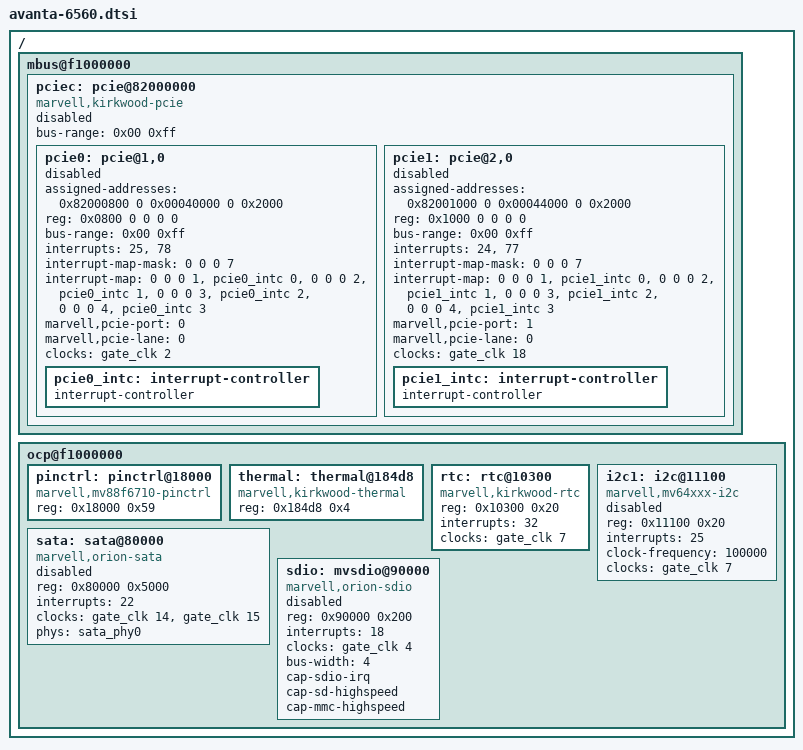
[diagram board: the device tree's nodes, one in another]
// SPDX-License-Identifier: GPL-2.0
/*
 *   (c) 2022 winnt5 <jiconglu58@gmail.com>
 *
 * Based on
 *
 * Copyright (c) 2021, bodhi <mibodhi@gmail.com>
 *
 * Based on    
 *   (c) 2015 Claudio Leite <leitec@staticky.com>
 *
 * Values derived from Marvell GPL source release, from Actiontec MI-424WR
 * source code,
 *
 *   Copyright (C) Marvell International Ltd. and its affiliates
 *
 * This file is licensed under the terms of the GNU General Public
 * License version 2.  This program is licensed "as is" without any
 * warranty of any kind, whether express or implied.
 */

/ {
	mbus@f1000000 {
		pciec: pcie@82000000 {
			compatible = "marvell,kirkwood-pcie";
			status = "disabled";
			device_type = "pci";

			#address-cells = <3>;
			#size-cells = <2>;

			bus-range = <0x00 0xff>;

			ranges =
			       <0x82000000 0 0x40000 MBUS_ID(0xf0, 0x01) 0x40000 0 0x00002000
			        0x82000000 0 0x44000 MBUS_ID(0xf0, 0x01) 0x44000 0 0x00002000
				0x82000000 0 0x80000 MBUS_ID(0xf0, 0x01) 0x80000 0 0x00002000
				0x82000000 0x1 0     MBUS_ID(0x04, 0xe8) 0       1 0 /* Port 0.0 MEM */
				0x81000000 0x1 0     MBUS_ID(0x04, 0xe0) 0       1 0 /* Port 0.0 IO  */
				0x82000000 0x2 0     MBUS_ID(0x04, 0xd8) 0       1 0 /* Port 1.0 MEM */
				0x81000000 0x2 0     MBUS_ID(0x04, 0xd0) 0       1 0 /* Port 1.0 IO  */>;

			pcie0: pcie@1,0 {
				device_type = "pci";
				assigned-addresses = <0x82000800 0 0x00040000 0 0x2000>;
				reg = <0x0800 0 0 0 0>;
				#address-cells = <3>;
				#size-cells = <2>;
				#interrupt-cells = <1>;
				ranges = <0x82000000 0 0 0x82000000 0x1 0 1 0
					  0x81000000 0 0 0x81000000 0x1 0 1 0>;
				bus-range = <0x00 0xff>;
				interrupt-names = "intx", "error";
				interrupts = <25>, <78>;
				interrupt-map-mask = <0 0 0 7>;
				interrupt-map = <0 0 0 1 &pcie0_intc 0>,
						<0 0 0 2 &pcie0_intc 1>,
						<0 0 0 3 &pcie0_intc 2>,
						<0 0 0 4 &pcie0_intc 3>;
				marvell,pcie-port = <0>;
				marvell,pcie-lane = <0>;
				clocks = <&gate_clk 2>;
				status = "disabled";

				pcie0_intc: interrupt-controller {
					interrupt-controller;
					#interrupt-cells = <1>;
				};
			};

			pcie1: pcie@2,0 {
				device_type = "pci";
				assigned-addresses = <0x82001000 0 0x00044000 0 0x2000>;
				reg = <0x1000 0 0 0 0>;
				#address-cells = <3>;
				#size-cells = <2>;
				#interrupt-cells = <1>;
				ranges = <0x82000000 0 0 0x82000000 0x2 0 1 0
					  0x81000000 0 0 0x81000000 0x2 0 1 0>;
				bus-range = <0x00 0xff>;
				interrupt-names = "intx", "error";
				interrupts = <24>, <77>;
				interrupt-map-mask = <0 0 0 7>;
				interrupt-map = <0 0 0 1 &pcie1_intc 0>,
						<0 0 0 2 &pcie1_intc 1>,
						<0 0 0 3 &pcie1_intc 2>,
						<0 0 0 4 &pcie1_intc 3>;
				marvell,pcie-port = <1>;
				marvell,pcie-lane = <0>;
				clocks = <&gate_clk 18>;
				status = "disabled";

				pcie1_intc: interrupt-controller {
					interrupt-controller;
					#interrupt-cells = <1>;
				};
			};
		};
	};
	ocp@f1000000 {
		pinctrl: pinctrl@18000 {
			compatible = "marvell,mv88f6710-pinctrl";
			reg = <0x18000 0x59>;
		};

		thermal: thermal@184d8 {
			compatible = "marvell,kirkwood-thermal";
			reg = <0x184d8 0x4>;
			status = "okay";
		};

		rtc: rtc@10300 {
			compatible = "marvell,kirkwood-rtc", "marvell,orion-rtc";
			reg = <0x10300 0x20>;
			interrupts = <32>;
			clocks = <&gate_clk 7>;
		};

		i2c1: i2c@11100 {
			compatible = "marvell,mv64xxx-i2c";
			reg = <0x11100 0x20>;
			#address-cells = <1>;
			#size-cells = <0>;
			interrupts = <25>;
			clock-frequency = <100000>;
			clocks = <&gate_clk 7>;
			status = "disabled";
		};

		sata: sata@80000 {
			compatible = "marvell,orion-sata";
			reg = <0x80000 0x5000>;
			interrupts = <22>;
			clocks = <&gate_clk 14>, <&gate_clk 15>;
			clock-names = "0", "1";
			phys = <&sata_phy0>;
			phy-names = "port0";
			status = "disabled";
		};

		sdio: mvsdio@90000 {
			compatible = "marvell,orion-sdio";
			reg = <0x90000 0x200>;
			interrupts = <18>;
			clocks = <&gate_clk 4>;
			bus-width = <4>;
			cap-sdio-irq;
			cap-sd-highspeed;
			cap-mmc-highspeed;
			status = "disabled";
		};
	};
};
